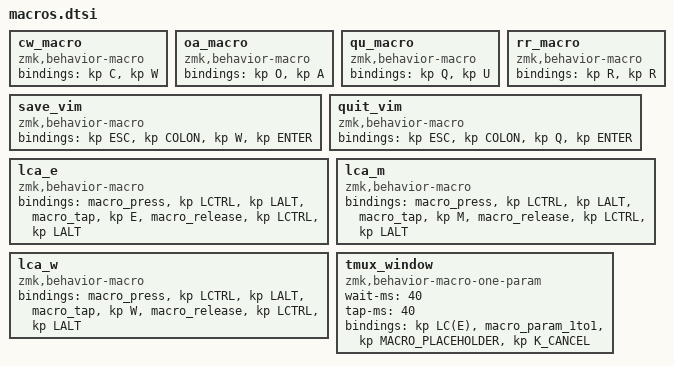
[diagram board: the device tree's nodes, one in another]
cw_macro: cw_macro {
    compatible = "zmk,behavior-macro";
    #binding-cells = <0>;
    bindings = <&kp C &kp W>;
};
oa_macro: oa_macro {
    compatible = "zmk,behavior-macro";
    #binding-cells = <0>;
    bindings = <&kp O &kp A>;
};
qu_macro: qu_macro {
    compatible = "zmk,behavior-macro";
    #binding-cells = <0>;
    bindings = <&kp Q &kp U>;
};
rr_macro: rr_macro {
    compatible = "zmk,behavior-macro";
    #binding-cells = <0>;
    bindings = <&kp R &kp R>;
};
save_vim: save_vim {
    compatible = "zmk,behavior-macro";
    #binding-cells = <0>;
    bindings
        = <&kp ESC &kp COLON &kp W &kp ENTER>
        ;
};
quit_vim: quit_vim {
    compatible = "zmk,behavior-macro";
    #binding-cells = <0>;
    bindings
        = <&kp ESC &kp COLON &kp Q &kp ENTER>
        ;
};
lca_e: lca_e {
    compatible = "zmk,behavior-macro";
    #binding-cells = <0>;
    bindings
          = <&macro_press &kp LCTRL &kp LALT>
          , <&macro_tap &kp E>
          , <&macro_release &kp LCTRL &kp LALT>
          ;
};
lca_m: lca_m {
    compatible = "zmk,behavior-macro";
    #binding-cells = <0>;
    bindings
          = <&macro_press &kp LCTRL &kp LALT>
          , <&macro_tap &kp M>
          , <&macro_release &kp LCTRL &kp LALT>
          ;
};
lca_w: lca_w {
    compatible = "zmk,behavior-macro";
    #binding-cells = <0>;
    bindings
          = <&macro_press &kp LCTRL &kp LALT>
          , <&macro_tap &kp W>
          , <&macro_release &kp LCTRL &kp LALT>
          ;
};
tmux_window: tmux_window {
    compatible = "zmk,behavior-macro-one-param";
    #binding-cells = <1>;
    wait-ms = <40>;
    tap-ms = <40>;
    bindings
        = <&kp LC(E)>
        , <&macro_param_1to1>
        , <&kp MACRO_PLACEHOLDER>
        , <&kp K_CANCEL>
        ;
};
